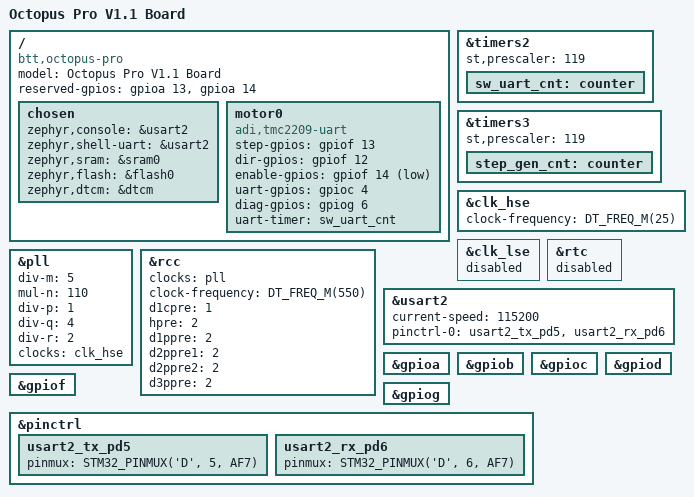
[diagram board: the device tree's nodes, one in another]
// SPDX-FileCopyrightText: 2025 夕月霞
// SPDX-License-Identifier: AGPL-3.0-or-later

/dts-v1/;
#include <st/h7/stm32h723Xg.dtsi>
#include <st/h7/stm32h723zgtx-pinctrl.dtsi>

/ {
	model = "Octopus Pro V1.1 Board";
	compatible = "btt,octopus-pro";

	chosen {
		zephyr,console = &usart2;
		zephyr,shell-uart = &usart2;
		zephyr,sram = &sram0;
		zephyr,flash = &flash0;
		zephyr,dtcm = &dtcm;
	};

	motor0: motor0 {
		compatible = "adi,tmc2209-uart";
		step-gpios = <&gpiof 13 GPIO_ACTIVE_HIGH>;
		dir-gpios = <&gpiof 12 GPIO_ACTIVE_HIGH>;
		enable-gpios = <&gpiof 14 GPIO_ACTIVE_LOW>;
		uart-gpios = <&gpioc 4 GPIO_ACTIVE_HIGH>;
		diag-gpios = <&gpiog 6 GPIO_ACTIVE_HIGH>;
		uart-timer = <&sw_uart_cnt>;
	};
};


&timers2 {
	status = "okay";
	st,prescaler = <119>; // 120MHz (APB1 clock) -> 1MHz tick

	sw_uart_cnt: counter {
		status = "okay";
	};
};

&timers3 {
	status = "okay";
	st,prescaler = <119>; // 120MHz (APB1 clock) -> 1MHz tick

	step_gen_cnt: counter {
		status = "okay";
	};
};

&clk_hse {
	clock-frequency = <DT_FREQ_M(25)>;
	status = "okay";
};

/* Disable LSE (32kHz external oscillator) to free up PC14/PC15 for GPIO */
&clk_lse {
	status = "disabled";
};

&rtc {
	status = "disabled";
};

&pll {
	div-m = <5>;
	mul-n = <110>;
	div-p = <1>;
	div-q = <4>;
	div-r = <2>;
	clocks = <&clk_hse>;
	status = "okay";
};

&rcc {
	clocks = <&pll>;
	clock-frequency = <DT_FREQ_M(550)>;
	d1cpre = <1>;
	hpre = <2>;
	d1ppre = <2>;
	d2ppre1 = <2>;
	d2ppre2 = <2>;
	d3ppre = <2>;
};

&usart2 {
	status = "okay";
	current-speed = <115200>;
	pinctrl-0 = <&usart2_tx_pd5 &usart2_rx_pd6>;
	pinctrl-names = "default";
};

/* Keep SWD pins available for debugging */
&gpioa {
	status = "okay";
};

&gpiob {
	status = "okay";
};

&gpioc {
	status = "okay";
};

&gpiod {
	status = "okay";
};

&gpiof {
	status = "okay";
};

&gpiog {
	status = "okay";
};

&pinctrl {
	/* USART2 can use PD5 (TX) and PD6 (RX) */
	usart2_tx_pd5: usart2_tx_pd5 {
		pinmux = <STM32_PINMUX('D', 5, AF7)>;
	};

	usart2_rx_pd6: usart2_rx_pd6 {
		pinmux = <STM32_PINMUX('D', 6, AF7)>;
	};
};


/* Reserve SWD pins PA13 (SWDIO) and PA14 (SWCLK) for debugging */
/ {
	reserved-gpios = <&gpioa 13 0>, <&gpioa 14 0>;
};
